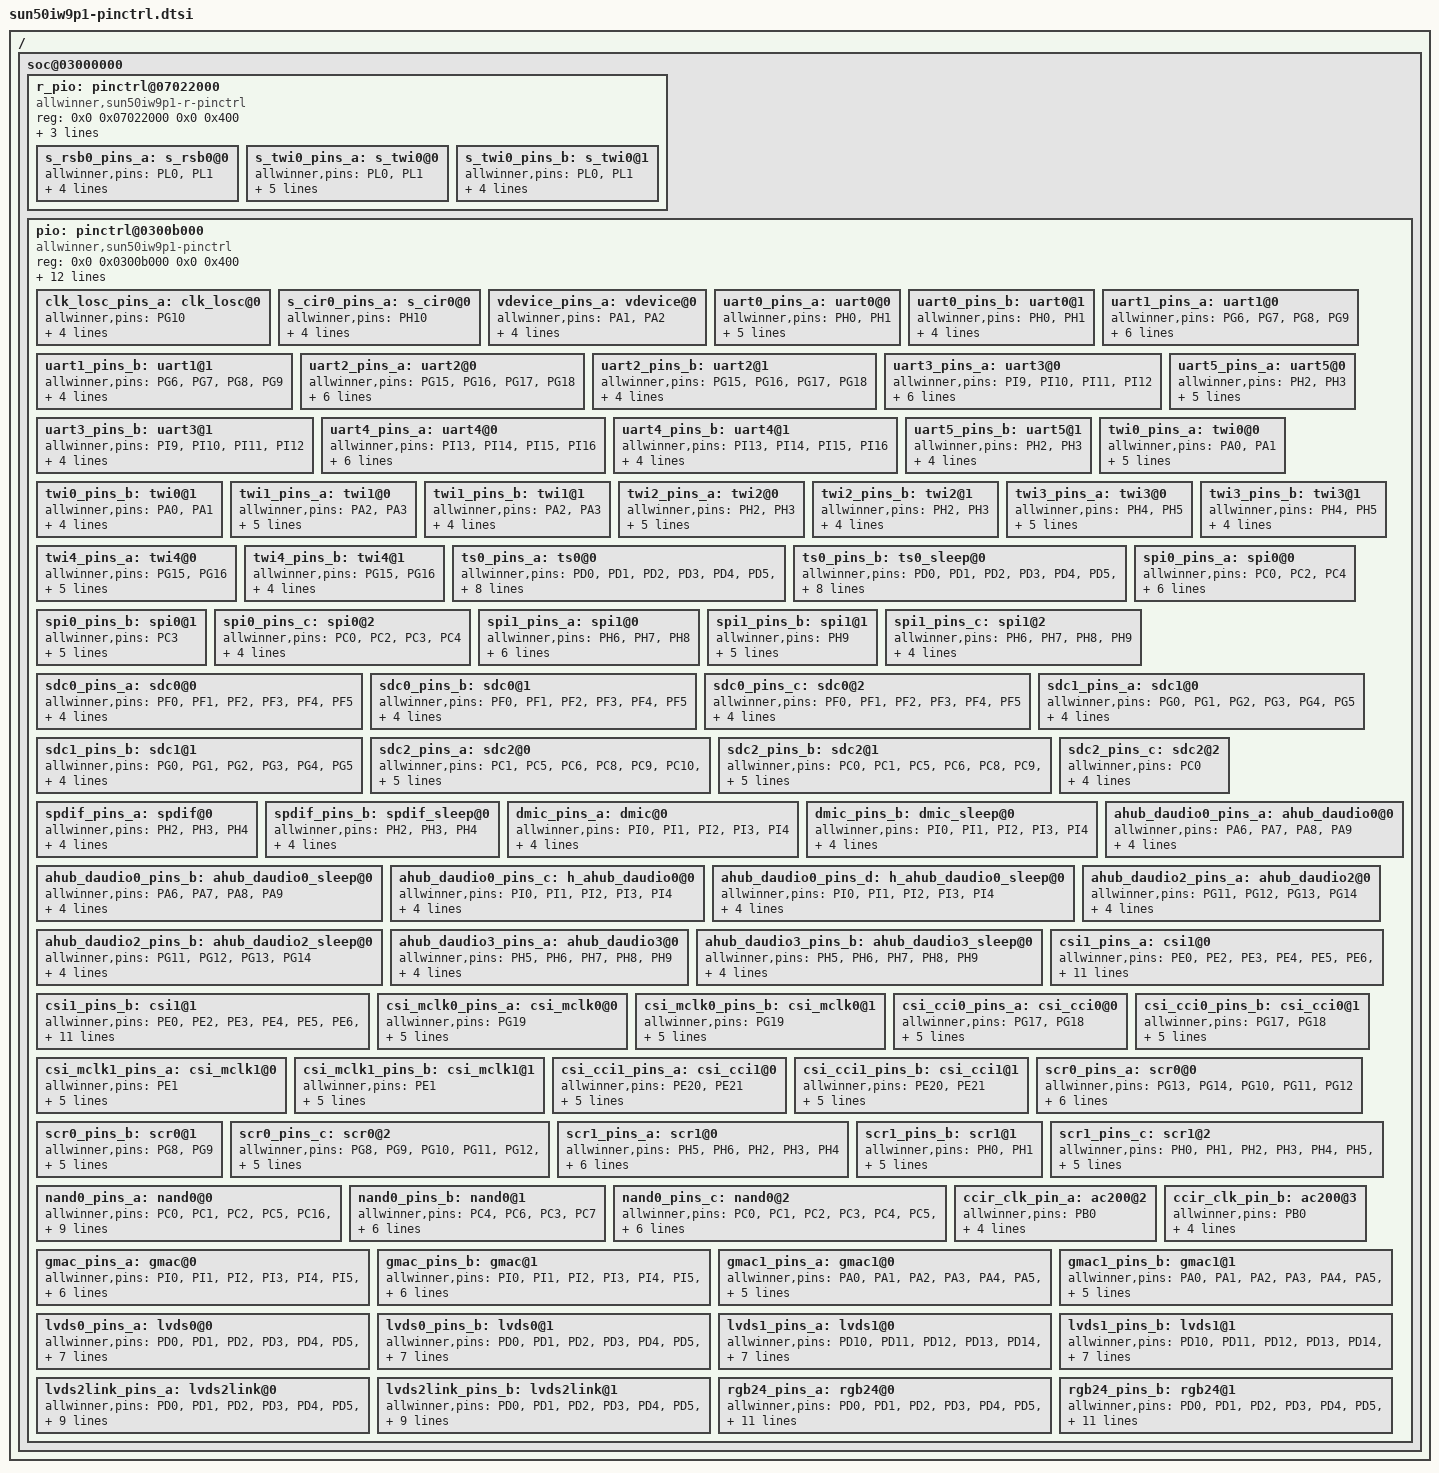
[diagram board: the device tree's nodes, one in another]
/*
 * Allwinner sun50iw9 pin config info.
 */

/ {
	soc@03000000{
		r_pio: pinctrl@07022000 {
			compatible = "allwinner,sun50iw9p1-r-pinctrl";
			reg = <0x0 0x07022000 0x0 0x400>;
			clocks = <&clk_cpurpio>;
			device_type = "r_pio";
			gpio-controller;
			interrupt-controller;
			#interrupt-cells = <3>;
			#size-cells = <0>;
			#gpio-cells = <6>;

			s_rsb0_pins_a: s_rsb0@0 {
				allwinner,pins = "PL0", "PL1";
				allwinner,function = "s_rsb0";
				allwinner,muxsel = <2>;
				allwinner,drive = <2>;
				allwinner,pull = <1>;
			};

			s_twi0_pins_a: s_twi0@0 {
				allwinner,pins = "PL0", "PL1";
				allwinner,pname = "s_twi0_scl", "s_twi0_sda";
				allwinner,function = "s_twi0";
				allwinner,muxsel = <3>;
				allwinner,drive = <1>;
				allwinner,pull = <1>;
			};

			s_twi0_pins_b: s_twi0@1 {
				allwinner,pins = "PL0", "PL1";
				allwinner,function = "io_disabled";
				allwinner,muxsel = <7>;
				allwinner,drive = <1>;
				allwinner,pull = <0>;
			};
		};

		pio: pinctrl@0300b000 {
			compatible = "allwinner,sun50iw9p1-pinctrl";
			reg = <0x0 0x0300b000 0x0 0x400>;
			interrupts = <GIC_SPI 51 IRQ_TYPE_LEVEL_HIGH>,  /* AW1823_GIC_Spec: GPIOA: 83-32=51 */
				     <GIC_SPI 52 IRQ_TYPE_LEVEL_HIGH>,
				     <GIC_SPI 53 IRQ_TYPE_LEVEL_HIGH>,
				     <GIC_SPI 43 IRQ_TYPE_LEVEL_HIGH>,
				     <GIC_SPI 54 IRQ_TYPE_LEVEL_HIGH>,
				     <GIC_SPI 55 IRQ_TYPE_LEVEL_HIGH>,
				     <GIC_SPI 56 IRQ_TYPE_LEVEL_HIGH>,
				     <GIC_SPI 57 IRQ_TYPE_LEVEL_HIGH>;
			device_type = "pio";
			clocks = <&clk_pio>, <&clk_losc>, <&clk_hosc>;
			gpio-controller;
			interrupt-controller;
			#interrupt-cells = <3>;
			#size-cells = <0>;
			#gpio-cells = <6>;
			/* takes the debounce time in usec as argument */
			input-debounce = <0 0 0 0 0 0 0>;

			clk_losc_pins_a: clk_losc@0 {
				allwinner,pins = "PG10";
				allwinner,function = "x32kfout";
				allwinner,muxsel = <3>;
				allwinner,drive = <2>;
				allwinner,pull = <1>;
			};

			s_cir0_pins_a: s_cir0@0{
					allwinner,pins = "PH10";
					allwinner,function = "ir";
					allwinner,muxsel = <3>;
					allwinner,drive = <2>;
					allwinner,pull = <1>;
			};

			vdevice_pins_a: vdevice@0 {
				allwinner,pins = "PA1", "PA2";
				allwinner,function = "Vdevice";
				allwinner,muxsel = <5>;
				allwinner,drive = <1>;
				allwinner,pull = <1>;
			};

			uart0_pins_a: uart0@0 {
				allwinner,pins = "PH0", "PH1";
				allwinner,pname = "uart0_tx", "uart0_rx";
				allwinner,function = "uart0";
				allwinner,muxsel = <2>;
				allwinner,drive = <1>;
				allwinner,pull = <1>;
			};

			uart0_pins_b: uart0@1 {
				allwinner,pins = "PH0", "PH1";
				allwinner,function = "uart0";  /* io_disabled */
				allwinner,muxsel = <7>;
				allwinner,drive = <1>;
				allwinner,pull = <0>;
			};
			uart1_pins_a: uart1@0 {
				allwinner,pins = "PG6", "PG7", "PG8", "PG9";
				allwinner,pname = "uart1_tx", "uart1_rx",
						  "uart1_rts", "uart1_cts";
				allwinner,function = "uart1";
				allwinner,muxsel = <2>;
				allwinner,drive = <1>;
				allwinner,pull = <1>;
			};

			uart1_pins_b: uart1@1 {
				allwinner,pins = "PG6", "PG7", "PG8", "PG9";
				allwinner,function = "io_disabled";
				allwinner,muxsel = <7>;
				allwinner,drive = <1>;
				allwinner,pull = <0>;
			};

			uart2_pins_a: uart2@0 {
				allwinner,pins = "PG15", "PG16", "PG17", "PG18";
				allwinner,pname = "uart2_tx", "uart2_rx",
						  "uart2_rts", "uart2_cts";
				allwinner,function = "uart2";
				allwinner,muxsel = <2>;
				allwinner,drive = <1>;
				allwinner,pull = <1>;
			};

			uart2_pins_b: uart2@1 {
				allwinner,pins = "PG15", "PG16", "PG17", "PG18";
				allwinner,function = "io_disabled";
				allwinner,muxsel = <7>;
				allwinner,drive = <1>;
				allwinner,pull = <0>;
			};

			uart3_pins_a: uart3@0 {
				allwinner,pins = "PI9", "PI10", "PI11", "PI12";
				allwinner,pname = "uart3_tx", "uart3_rx",
						  "uart3_rts", "uart3_cts";
				allwinner,function = "uart3";
				allwinner,muxsel = <3>;
				allwinner,drive = <1>;
				allwinner,pull = <1>;
			};

			uart3_pins_b: uart3@1 {
				allwinner,pins = "PI9", "PI10", "PI11", "PI12";
				allwinner,function = "io_disabled";
				allwinner,muxsel = <7>;
				allwinner,drive = <1>;
				allwinner,pull = <0>;
			};

			uart4_pins_a: uart4@0 {
				allwinner,pins = "PI13", "PI14", "PI15", "PI16";
				allwinner,pname = "uart4_tx", "uart4_rx",
						  "uart4_rts", "uart4_cts";
				allwinner,function = "uart4";
				allwinner,muxsel = <3>;
				allwinner,drive = <1>;
				allwinner,pull = <1>;
			};

			uart4_pins_b: uart4@1 {
				allwinner,pins = "PI13", "PI14", "PI15", "PI16";
				allwinner,function = "io_disabled";
				allwinner,muxsel = <7>;
				allwinner,drive = <1>;
				allwinner,pull = <0>;
			};

			uart5_pins_a: uart5@0 {
				allwinner,pins = "PH2", "PH3";
				allwinner,pname = "uart3_tx", "uart3_rx";
				allwinner,function = "uart5";
				allwinner,muxsel = <2>;
				allwinner,drive = <1>;
				allwinner,pull = <1>;
			};

			uart5_pins_b: uart5@1 {
				allwinner,pins = "PH2", "PH3";
				allwinner,function = "io_disabled";
				allwinner,muxsel = <7>;
				allwinner,drive = <1>;
				allwinner,pull = <0>;
			};

			twi0_pins_a: twi0@0 {
				allwinner,pins = "PA0", "PA1";
				allwinner,pname = "twi0_scl", "twi0_sda";
				allwinner,function = "twi0";
				allwinner,muxsel = <4>;
				allwinner,drive = <1>;
				allwinner,pull = <0>;
			};

			twi0_pins_b: twi0@1 {
				allwinner,pins = "PA0", "PA1";
				allwinner,function = "io_disabled";
				allwinner,muxsel = <7>;
				allwinner,drive = <1>;
				allwinner,pull = <0>;
			};

			twi1_pins_a: twi1@0 {
				allwinner,pins = "PA2", "PA3";
				allwinner,pname = "twi1_scl", "twi1_sda";
				allwinner,function = "twi1";
				allwinner,muxsel = <4>;
				allwinner,drive = <1>;
				allwinner,pull = <0>;
			};

			twi1_pins_b: twi1@1 {
				allwinner,pins = "PA2", "PA3";
				allwinner,function = "io_disabled";
				allwinner,muxsel = <7>;
				allwinner,drive = <1>;
				allwinner,pull = <0>;
			};

			twi2_pins_a: twi2@0 {
				allwinner,pins = "PH2", "PH3";
				allwinner,pname = "twi2_scl", "twi2_sda";
				allwinner,function = "twi2";
				allwinner,muxsel = <5>;
				allwinner,drive = <1>;
				allwinner,pull = <0>;
			};

			twi2_pins_b: twi2@1 {
				allwinner,pins = "PH2", "PH3";
				allwinner,function = "io_disabled";
				allwinner,muxsel = <7>;
				allwinner,drive = <1>;
				allwinner,pull = <0>;
			};

			twi3_pins_a: twi3@0 {
				allwinner,pins = "PH4", "PH5";
				allwinner,pname = "twi3_scl", "twi3_sda";
				allwinner,function = "twi3";
				allwinner,muxsel = <5>;
				allwinner,drive = <1>;
				allwinner,pull = <0>;
			};

			twi3_pins_b: twi3@1 {
				allwinner,pins = "PH4", "PH5";
				allwinner,function = "io_disabled";
				allwinner,muxsel = <7>;
				allwinner,drive = <1>;
				allwinner,pull = <0>;
			};

			twi4_pins_a: twi4@0 {
				allwinner,pins = "PG15", "PG16";
				allwinner,pname = "twi4_scl", "twi4_sda";
				allwinner,function = "twi4";
				allwinner,muxsel = <2>;
				allwinner,drive = <1>;
				allwinner,pull = <0>;
			};

			twi4_pins_b: twi4@1 {
				allwinner,pins = "PG15", "PG16";
				allwinner,function = "io_disabled";
				allwinner,muxsel = <7>;
				allwinner,drive = <1>;
				allwinner,pull = <0>;
			};

			ts0_pins_a: ts0@0 {
				allwinner,pins = "PD0", "PD1", "PD2", "PD3",
						 "PD4", "PD5", "PD6", "PD7",
						 "PD8", "PD9", "PD10", "PD11";
				allwinner,pname = "ts0_clk", "ts0_err",
						  "ts0_sync", "ts0_dvld",
						  "ts0_d0", "ts0_d1",
						  "ts0_d2", "ts0_d3",
						  "ts0_d4", "ts0_d5",
						  "ts0_d6", "ts0_d7";
				allwinner,function = "ts0";
				allwinner,muxsel = <4>;
				allwinner,drive = <1>;
				allwinner,pull = <0>;
			};

			ts0_pins_b: ts0_sleep@0 {
				allwinner,pins = "PD0", "PD1", "PD2", "PD3",
						 "PD4", "PD5", "PD6", "PD7",
						 "PD8", "PD9", "PD10", "PD11";
				allwinner,pname = "ts0_clk", "ts0_err",
						  "ts0_sync", "ts0_dvld",
						  "ts0_d0", "ts0_d1",
						  "ts0_d2", "ts0_d3",
						  "ts0_d4", "ts0_d5",
						  "ts0_d6", "ts0_d7";
				allwinner,function = "io_disabled";
				allwinner,muxsel = <7>;
				allwinner,drive = <1>;
				allwinner,pull = <0>;
			};

			spi0_pins_a: spi0@0 {
				allwinner,pins = "PC0", "PC2", "PC4";
				allwinner,pname = "spi0_sclk", "spi0_mosi",
						  "spi0_miso";
				allwinner,function = "spi0";
				allwinner,muxsel = <4>;
				allwinner,drive = <1>;
				allwinner,pull = <0>;
			};

			spi0_pins_b: spi0@1 {
				allwinner,pins = "PC3";
				allwinner,pname = "spi0_cs0";
				allwinner,function = "spi0";
				allwinner,muxsel = <4>;
				allwinner,drive = <1>;
				allwinner,pull = <1>;	// only CS should be pulled up
			};

			spi0_pins_c: spi0@2 {
				allwinner,pins = "PC0", "PC2", "PC3", "PC4";
				allwinner,function = "io_disabled";
				allwinner,muxsel = <7>;
				allwinner,drive = <1>;
				allwinner,pull = <0>;
			};

			spi1_pins_a: spi1@0 {
				allwinner,pins = "PH6", "PH7", "PH8";
				allwinner,pname = "spi1_sclk", "spi1_mosi",
						  "spi1_miso";
				allwinner,function = "spi1";
				allwinner,muxsel = <4>;
				allwinner,drive = <1>;
				allwinner,pull = <0>;
			};

			spi1_pins_b: spi1@1 {
				allwinner,pins = "PH9";
				allwinner,pname = "spi1_cs1";
				allwinner,function = "spi1";
				allwinner,muxsel = <4>;
				allwinner,drive = <1>;
				allwinner,pull = <1>;	// only CS should be pulled up
			};

			spi1_pins_c: spi1@2 {
				allwinner,pins = "PH6", "PH7", "PH8", "PH9";
				allwinner,function = "io_disabled";
				allwinner,muxsel = <7>;
				allwinner,drive = <1>;
				allwinner,pull = <0>;
			};

			sdc0_pins_a: sdc0@0 {
				allwinner,pins = "PF0", "PF1", "PF2",
						 "PF3", "PF4", "PF5";
				allwinner,function = "sdc0";
				allwinner,muxsel = <2>;
				allwinner,drive = <3>;
				allwinner,pull = <1>;
			};

			sdc0_pins_b: sdc0@1 {
				allwinner,pins = "PF0", "PF1", "PF2",
						 "PF3", "PF4", "PF5";
				allwinner,function = "io_disabled";
				allwinner,muxsel = <7>;
				allwinner,drive = <1>;
				allwinner,pull = <1>;
			};

			sdc0_pins_c: sdc0@2 {
				allwinner,pins = "PF0", "PF1", "PF2",
						 "PF3", "PF4", "PF5";
				allwinner,function = "uart0_jtag";
				allwinner,muxsel = <3>;
				allwinner,drive = <1>;
				allwinner,pull = <1>;
			};

			sdc1_pins_a: sdc1@0 {
				allwinner,pins = "PG0", "PG1", "PG2",
						 "PG3", "PG4", "PG5";
				allwinner,function = "sdc1";
				allwinner,muxsel = <2>;
				allwinner,drive = <3>;
				allwinner,pull = <1>;
			};

			sdc1_pins_b: sdc1@1 {
				allwinner,pins = "PG0", "PG1", "PG2",
						 "PG3", "PG4", "PG5";
				allwinner,function = "io_disabled";
				allwinner,muxsel = <7>;
				allwinner,drive = <1>;
				allwinner,pull = <1>;
			};

			sdc2_pins_a: sdc2@0 {
				allwinner,pins = "PC1", "PC5", "PC6",
						 "PC8", "PC9", "PC10", "PC11",
						 "PC13", "PC14", "PC15", "PC16";
				allwinner,function = "sdc2";
				allwinner,muxsel = <3>;
				allwinner,drive = <2>;
				allwinner,pull = <1>;
			};

			sdc2_pins_b: sdc2@1 {
				allwinner,pins = "PC0", "PC1", "PC5", "PC6",
						 "PC8", "PC9", "PC10", "PC11",
						 "PC13", "PC14", "PC15", "PC16";
				allwinner,function = "io_disabled";
				allwinner,muxsel = <7>;
				allwinner,drive = <1>;
				allwinner,pull = <1>;
			};

			sdc2_pins_c: sdc2@2 {
				allwinner,pins = "PC0";
				allwinner,function = "sdc2";
				allwinner,muxsel = <3>;
				allwinner,drive = <2>;
				allwinner,pull = <2>;
			};

			spdif_pins_a: spdif@0 {
				allwinner,pins = "PH2", "PH3", "PH4";
				allwinner,function = "spdif";
				allwinner,muxsel = <3>;
				allwinner,drive = <1>;
				allwinner,pull = <0>;
			};

			spdif_pins_b: spdif_sleep@0 {
				allwinner,pins = "PH2", "PH3", "PH4";
				allwinner,function = "io_disabled";
				allwinner,muxsel = <7>;
				allwinner,drive = <1>;
				allwinner,pull = <0>;
			};

			dmic_pins_a: dmic@0 {
				allwinner,pins = "PI0", "PI1", "PI2", "PI3", "PI4";
				allwinner,function = "dmic";
				allwinner,muxsel = <3>;
				allwinner,drive = <1>;
				allwinner,pull = <0>;
			};

			dmic_pins_b: dmic_sleep@0 {
				allwinner,pins = "PI0", "PI1", "PI2", "PI3", "PI4";
				allwinner,function = "io_disabled";
				allwinner,muxsel = <7>;
				allwinner,drive = <1>;
				allwinner,pull = <0>;
			};

			/* this set of daudio0 pins is used for t507 board */
			ahub_daudio0_pins_a: ahub_daudio0@0 {
				allwinner,pins = "PA6", "PA7", "PA8", "PA9";
				allwinner,function = "h_pcm0";
				allwinner,muxsel = <3>;
				allwinner,drive = <1>;
				allwinner,pull = <0>;
			};

			ahub_daudio0_pins_b: ahub_daudio0_sleep@0 {
				allwinner,pins = "PA6", "PA7", "PA8", "PA9";
				allwinner,function = "io_disabled";
				allwinner,muxsel = <7>;
				allwinner,drive = <1>;
				allwinner,pull = <0>;
			};

			/* this set of daudio0 pins is used for h616 board */
			ahub_daudio0_pins_c: h_ahub_daudio0@0 {
				allwinner,pins = "PI0", "PI1", "PI2", "PI3", "PI4";
				allwinner,function = "h_pcm0";
				allwinner,muxsel = <4>;
				allwinner,drive = <1>;
				allwinner,pull = <0>;
			};

			ahub_daudio0_pins_d: h_ahub_daudio0_sleep@0 {
				allwinner,pins = "PI0", "PI1", "PI2", "PI3", "PI4";
				allwinner,function = "io_disabled";
				allwinner,muxsel = <7>;
				allwinner,drive = <1>;
				allwinner,pull = <0>;
			};

			ahub_daudio2_pins_a: ahub_daudio2@0 {
				allwinner,pins = "PG11", "PG12", "PG13", "PG14";
				allwinner,function = "h_pcm2";
				allwinner,muxsel = <2>;
				allwinner,drive = <1>;
				allwinner,pull = <0>;
			};

			ahub_daudio2_pins_b: ahub_daudio2_sleep@0 {
				allwinner,pins = "PG11", "PG12", "PG13", "PG14";
				allwinner,function = "io_disabled";
				allwinner,muxsel = <7>;
				allwinner,drive = <1>;
				allwinner,pull = <0>;
			};

			ahub_daudio3_pins_a: ahub_daudio3@0 {
				allwinner,pins = "PH5", "PH6", "PH7", "PH8", "PH9";
				allwinner,function = "h_pcm3";
				allwinner,muxsel = <3>;
				allwinner,drive = <1>;
				allwinner,pull = <0>;
			};

			ahub_daudio3_pins_b: ahub_daudio3_sleep@0 {
				allwinner,pins = "PH5", "PH6", "PH7", "PH8", "PH9";
				allwinner,function = "io_disabled";
				allwinner,muxsel = <7>;
				allwinner,drive = <1>;
				allwinner,pull = <0>;
			};

			csi1_pins_a: csi1@0 {
				allwinner,pins = "PE0", "PE2", "PE3", "PE4", "PE5",
						 "PE6", "PE7", "PE8", "PE9", "PE10", "PE11",
						 "PE12", "PE13", "PE14", "PE15", "PE16", "PE17",
						  "PE18", "PE19";
				allwinner,pname = "csi1_pck", "csi1_hsync", "csi1_vsync",
						  "csi1_d0", "csi1_d1", "csi1_d2", "csi1_d3",
						  "csi1_d4", "csi1_d5", "csi1_d6", "csi1_d7",
						  "csi1_d8", "csi1_d9", "csi1_d10", "csi1_d11",
						  "csi1_d12", "csi1_d13", "csi1_d14", "csi1_d15";
				allwinner,function = "csi1";
				allwinner,muxsel = <2>;
				allwinner,drive = <1>;
				allwinner,pull = <0>;
			};

			csi1_pins_b: csi1@1 {
				allwinner,pins = "PE0", "PE2", "PE3", "PE4", "PE5",
						 "PE6", "PE7", "PE8", "PE9", "PE10", "PE11",
						 "PE12", "PE13", "PE14", "PE15", "PE16", "PE17",
						  "PE18", "PE19";
				allwinner,pname = "csi1_pck", "csi1_hsync", "csi1_vsync",
						  "csi1_d0", "csi1_d1", "csi1_d2", "csi1_d3",
						  "csi1_d4", "csi1_d5", "csi1_d6", "csi1_d7",
						  "csi1_d8", "csi1_d9", "csi1_d10", "csi1_d11",
						  "csi1_d12", "csi1_d13", "csi1_d14", "csi1_d15";
				allwinner,function = "io_disabled";
				allwinner,muxsel = <7>;
				allwinner,drive = <1>;
				allwinner,pull = <0>;
			};
			csi_mclk0_pins_a: csi_mclk0@0 {
				allwinner,pins = "PG19";
				allwinner,pname = "csi_mclk0";
				allwinner,function = "csi_mclk0";
				allwinner,muxsel = <3>;
				allwinner,drive = <2>;
				allwinner,pull = <0>;
			};
			csi_mclk0_pins_b: csi_mclk0@1 {
				allwinner,pins = "PG19";
				allwinner,pname = "csi_mclk0";
				allwinner,function = "io_disabled";
				allwinner,muxsel = <7>;
				allwinner,drive = <2>;
				allwinner,pull = <0>;
			};
			csi_cci0_pins_a: csi_cci0@0 {
				allwinner,pins = "PG17","PG18";
				allwinner,pname = "csi_cci0_sck","csi_cci0_sda";
				allwinner,function = "csi_cci0";
				allwinner,muxsel = <3>;
				allwinner,drive = <2>;
				allwinner,pull = <0>;
			};
			csi_cci0_pins_b: csi_cci0@1 {
				allwinner,pins = "PG17","PG18";
				allwinner,pname = "csi_cci0_sck","csi_cci0_sda";
				allwinner,function = "io_disabled";
				allwinner,muxsel = <7>;
				allwinner,drive = <2>;
				allwinner,pull = <0>;
			};
			csi_mclk1_pins_a: csi_mclk1@0 {
				allwinner,pins = "PE1";
				allwinner,pname = "csi_mclk1";
				allwinner,function = "csi_mclk1";
				allwinner,muxsel = <2>;
				allwinner,drive = <2>;
				allwinner,pull = <0>;
			};
			csi_mclk1_pins_b: csi_mclk1@1 {
				allwinner,pins = "PE1";
				allwinner,pname = "csi_mclk1";
				allwinner,function = "io_disabled";
				allwinner,muxsel = <7>;
				allwinner,drive = <2>;
				allwinner,pull = <0>;
			};
			csi_cci1_pins_a: csi_cci1@0 {
				allwinner,pins = "PE20","PE21";
				allwinner,pname = "csi_cci1_sck","csi_cci1_sda";
				allwinner,function = "csi_cci1";
				allwinner,muxsel = <2>;
				allwinner,drive = <2>;
				allwinner,pull = <0>;
			};
			csi_cci1_pins_b: csi_cci1@1 {
				allwinner,pins = "PE20","PE21";
				allwinner,pname = "csi_cci1_sck","csi_cci1_sda";
				allwinner,function = "io_disabled";
				allwinner,muxsel = <7>;
				allwinner,drive = <2>;
				allwinner,pull = <0>;
			};
			scr0_pins_a: scr0@0 {
				allwinner,pins = "PG13", "PG14", "PG10", "PG11", "PG12";
				allwinner,pname = "scr0_rst", "scr0_det", "scr0_vccen", "scr0_sck", "scr0_sda";
				allwinner,function = "sim0";
				allwinner,muxsel = <4>;
				allwinner,drive = <0>;
				allwinner,pull = <1>;
			};

			scr0_pins_b: scr0@1 {
				allwinner,pins = "PG8", "PG9";
				allwinner,pname = "scr0_vppen", "scr0_vppp";
				allwinner,function = "sim0";
				allwinner,muxsel = <4>;
				allwinner,drive = <0>;
				allwinner,pull = <1>;
			};

			scr0_pins_c: scr0@2 {
				allwinner,pins = "PG8", "PG9", "PG10", "PG11", "PG12", "PG13", "PG14";
				allwinner,function = "io_disabled";
				allwinner,muxsel = <7>;
				allwinner,drive = <0>;
				allwinner,pull = <0>;
			};

			scr1_pins_a: scr1@0 {
				allwinner,pins = "PH5", "PH6", "PH2",
						 "PH3", "PH4";
				allwinner,pname = "scr1_rst", "scr1_det",
						  "scr1_vccen", "scr1_sck",
						  "scr1_sda";
				allwinner,function = "sim1";
				allwinner,muxsel = <5>;
				allwinner,drive = <1>;
				allwinner,pull = <1>;
			};

			scr1_pins_b: scr1@1 {
				allwinner,pins = "PH0", "PH1";
				allwinner,pname = "scr1_vppen", "scr1_vppp";
				allwinner,function = "sim1";
				allwinner,muxsel = <5>;
				allwinner,drive = <1>;
				allwinner,pull = <1>;
			};

			scr1_pins_c: scr1@2 {
				allwinner,pins = "PH0", "PH1", "PH2",
						 "PH3", "PH4", "PH5",
						 "PH6";
				allwinner,function = "io_disabled";
				allwinner,muxsel = <7>;
				allwinner,drive = <1>;
				allwinner,pull = <0>;
			};

			nand0_pins_a: nand0@0 {
				allwinner,pins = "PC0", "PC1", "PC2", "PC5",
						 "PC16", "PC15", "PC14", "PC13",
						 "PC11", "PC10", "PC9", "PC8",
						 "PC12";
				allwinner,pname= "nand0_we", "nand0_ale","nand0_cle", "nand0_nre",
						 "nand0_d0", "nand0_d1", "nand0_d2", "nand0_d3",
						 "nand0_d4", "nand0_d5", "nand0_d6", "nand0_d7",
						 "nand0_ndqs";
				allwinner,function = "nand0";
				allwinner,muxsel = <2>;
				allwinner,drive = <1>;
				allwinner,pull = <0>;
			};

			nand0_pins_b: nand0@1 {
				allwinner,pins = "PC4", "PC6", "PC3", "PC7";
				allwinner,pname= "nand0_ce0", "nand0_rb0", "nand0_ce1", "nand0_rb1";
				allwinner,function = "nand0";
				allwinner,muxsel = <2>;
				allwinner,drive = <1>;
				allwinner,pull = <1>;// only RB&CE should be pulled up
			};

			nand0_pins_c: nand0@2 {
				allwinner,pins = "PC0", "PC1", "PC2", "PC3",
						 "PC4", "PC5", "PC6", "PC7",
						 "PC8", "PC9", "PC10", "PC11",
						 "PC12", "PC13", "PC14", "PC15",
						 "PC16";
				allwinner,function = "io_disabled";
				allwinner,muxsel = <7>;
				allwinner,drive = <1>;
				allwinner,pull = <0>;
			};

			ccir_clk_pin_a: ac200@2 {
				allwinner,pins = "PB0";
				allwinner,function = "ac200";
				allwinner,muxsel = <2>;
				allwinner,drive = <1>;
				allwinner,pull = <0>;
			};

			ccir_clk_pin_b: ac200@3 {
				allwinner,pins = "PB0";
				allwinner,function = "io_disabled";
				allwinner,muxsel = <7>;
				allwinner,drive = <1>;
				allwinner,pull = <0>;
			};

			gmac_pins_a: gmac@0 {
				allwinner,pins = "PI0", "PI1", "PI2", "PI3",
						 "PI4", "PI5", "PI7",
						 "PI8", "PI9", "PI10", "PI11",
						 "PI12", "PI13", "PI14", "PI15";
				allwinner,function = "gmac0";
				allwinner,muxsel = <2>;
				allwinner,drive = <3>;
				allwinner,pull = <0>;
			};

			gmac_pins_b: gmac@1 {
				allwinner,pins = "PI0", "PI1", "PI2", "PI3",
						 "PI4", "PI5", "PI7",
						 "PI8", "PI9", "PI10", "PI11",
						 "PI12", "PI13", "PI14", "PI15";
				allwinner,function = "io_disabled";
				allwinner,muxsel = <7>;
				allwinner,drive = <3>;
				allwinner,pull = <0>;
			};

			gmac1_pins_a: gmac1@0 {
				allwinner,pins = "PA0", "PA1", "PA2", "PA3",
						 "PA4", "PA5", "PA6", "PA7",
						 "PA8", "PA9";
				allwinner,function = "gmac1";
				allwinner,muxsel = <2>;
				allwinner,drive = <3>;
				allwinner,pull = <0>;
			};

			gmac1_pins_b: gmac1@1 {
				allwinner,pins = "PA0", "PA1", "PA2", "PA3",
						 "PA4", "PA5", "PA6", "PA7",
						 "PA8", "PA9";
				allwinner,function = "io_disabled";
				allwinner,muxsel = <7>;
				allwinner,drive = <3>;
				allwinner,pull = <0>;
			};

			lvds0_pins_a: lvds0@0 {
				allwinner,pins = "PD0", "PD1", "PD2", "PD3", "PD4", "PD5", "PD8", "PD9", "PD6", "PD7";
				allwinner,pname = "PD0", "PD1", "PD2", "PD3", "PD4", "PD5", "PD8", "PD9", "PD6", "PD7";
				allwinner,function = "lvds0";
				allwinner,muxsel = <3>;
				allwinner,drive = <3>;
				allwinner,pull = <0>;
			};
			lvds0_pins_b: lvds0@1 {
				allwinner,pins = "PD0", "PD1", "PD2", "PD3", "PD4", "PD5", "PD8", "PD9", "PD6", "PD7";
				allwinner,pname = "PD0", "PD1", "PD2", "PD3", "PD4", "PD5", "PD8", "PD9", "PD6", "PD7";
				allwinner,function = "lvds0_suspend";
				allwinner,muxsel = <7>;
				allwinner,drive = <3>;
				allwinner,pull = <0>;
			};

			lvds1_pins_a: lvds1@0 {
				allwinner,pins = "PD10", "PD11", "PD12", "PD13", "PD14", "PD15", "PD18", "PD19", "PD16", "PD17";
				allwinner,pname = "PD10", "PD11", "PD12", "PD13", "PD14", "PD15", "PD18", "PD19", "PD16", "PD17";
				allwinner,function = "lvds1";
				allwinner,muxsel = <3>;
				allwinner,drive = <3>;
				allwinner,pull = <0>;
			};
			lvds1_pins_b: lvds1@1 {
				allwinner,pins = "PD10", "PD11", "PD12", "PD13", "PD14", "PD15", "PD18", "PD19", "PD16", "PD17";
				allwinner,pname = "PD10", "PD11", "PD12", "PD13", "PD14", "PD15", "PD18", "PD19", "PD16", "PD17";
				allwinner,function = "lvds1_suspend";
				allwinner,muxsel = <7>;
				allwinner,drive = <3>;
				allwinner,pull = <0>;
			};

			lvds2link_pins_a: lvds2link@0 {
				allwinner,pins = "PD0", "PD1", "PD2", "PD3", "PD4", "PD5", "PD8", "PD9", "PD6", "PD7", \
				"PD10", "PD11", "PD12", "PD13", "PD14", "PD15", "PD18", "PD19", "PD16", "PD17";
				allwinner,pname = "PD0", "PD1", "PD2", "PD3", "PD4", "PD5", "PD8", "PD9", "PD6", "PD7", \
				"PD10", "PD11", "PD12", "PD13", "PD14", "PD15", "PD18", "PD19", "PD16", "PD17";
				allwinner,function = "lvds1";
				allwinner,muxsel = <3>;
				allwinner,drive = <3>;
				allwinner,pull = <0>;
			};
			lvds2link_pins_b: lvds2link@1 {
				allwinner,pins = "PD0", "PD1", "PD2", "PD3", "PD4", "PD5", "PD8", "PD9", "PD6", "PD7", \
				"PD10", "PD11", "PD12", "PD13", "PD14", "PD15", "PD18", "PD19", "PD16", "PD17";
				allwinner,pname = "PD0", "PD1", "PD2", "PD3", "PD4", "PD5", "PD8", "PD9", "PD6", "PD7", \
				"PD10", "PD11", "PD12", "PD13", "PD14", "PD15", "PD18", "PD19", "PD16", "PD17";
				allwinner,function = "lvds1_suspend";
				allwinner,muxsel = <7>;
				allwinner,drive = <3>;
				allwinner,pull = <0>;
			};

			rgb24_pins_a: rgb24@0 {
				allwinner,pins = "PD0", "PD1", "PD2", "PD3", "PD4", "PD5", "PD6", "PD7", "PD8", "PD9", \
				"PD10", "PD11", "PD12", "PD13", "PD14", "PD15", "PD16", "PD17", "PD18", "PD19", \
				"PD20", "PD21", "PD22", "PD23", "PD24", "PD25", "PD26", "PD27";
				allwinner,pname = "PD0", "PD1", "PD2", "PD3", "PD4", "PD5", "PD6", "PD7", "PD8", "PD9", \
				"PD10", "PD11", "PD12", "PD13", "PD14", "PD15", "PD16", "PD17", "PD18", "PD19", \
				"PD20", "PD21", "PD22", "PD23", "PD24", "PD25", "PD26", "PD27";
				allwinner,function = "rgb24";
				allwinner,muxsel = <2>;
				allwinner,drive = <3>;
				allwinner,pull = <0>;
			};
			rgb24_pins_b: rgb24@1 {
				allwinner,pins = "PD0", "PD1", "PD2", "PD3", "PD4", "PD5", "PD6", "PD7", "PD8", "PD9", \
				"PD10", "PD11", "PD12", "PD13", "PD14", "PD15", "PD16", "PD17", "PD18", "PD19", \
				"PD20", "PD21", "PD22", "PD23", "PD24", "PD25", "PD26", "PD27";
				allwinner,pname = "PD0", "PD1", "PD2", "PD3", "PD4", "PD5", "PD6", "PD7", "PD8", "PD9", \
				"PD10", "PD11", "PD12", "PD13", "PD14", "PD15", "PD16", "PD17", "PD18", "PD19", \
				"PD20", "PD21", "PD22", "PD23", "PD24", "PD25", "PD26", "PD27";
				allwinner,function = "rgb24_suspend";
				allwinner,muxsel = <7>;
				allwinner,drive = <3>;
				allwinner,pull = <0>;
			};
		};
	};
};
